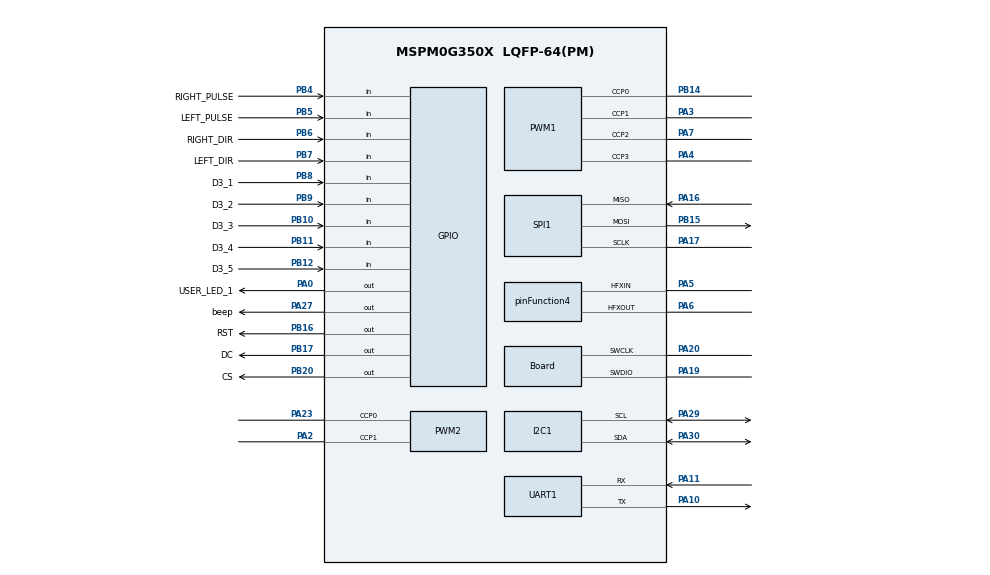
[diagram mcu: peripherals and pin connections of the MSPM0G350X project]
/**
 * @cliArgs --device "MSPM0G350X" --package "LQFP-64(PM)" --part "Default" --product "mspm0_sdk@2.01.00.03"
 * @versions {"tool":"1.20.0+3587"}
 */

/**
 * Import the modules used in this configuration.
 */
const ADC12         = scripting.addModule("/ti/driverlib/ADC12", {}, false);
const ADC121        = ADC12.addInstance();
const Board         = scripting.addModule("/ti/driverlib/Board");
const GPIO          = scripting.addModule("/ti/driverlib/GPIO", {}, false);
const GPIO1         = GPIO.addInstance();
const GPIO2         = GPIO.addInstance();
const GPIO3         = GPIO.addInstance();
const GPIO4         = GPIO.addInstance();
const GPIO5         = GPIO.addInstance();
const GPIO6         = GPIO.addInstance();
const I2C           = scripting.addModule("/ti/driverlib/I2C", {}, false);
const I2C1          = I2C.addInstance();
const PWM           = scripting.addModule("/ti/driverlib/PWM", {}, false);
const PWM1          = PWM.addInstance();
const PWM2          = PWM.addInstance();
const SPI           = scripting.addModule("/ti/driverlib/SPI", {}, false);
const SPI1          = SPI.addInstance();
const SYSCTL        = scripting.addModule("/ti/driverlib/SYSCTL");
const TIMER         = scripting.addModule("/ti/driverlib/TIMER", {}, false);
const TIMER1        = TIMER.addInstance();
const UART          = scripting.addModule("/ti/driverlib/UART", {}, false);
const UART1         = UART.addInstance();
const ProjectConfig = scripting.addModule("/ti/project_config/ProjectConfig");

/**
 * Write custom configuration values to the imported modules.
 */
const divider2       = system.clockTree["HFCLK4MFPCLKDIV"];
divider2.divideValue = 10;

const divider6       = system.clockTree["PLL_CLK2X_DIV"];
divider6.divideValue = 4;

const divider9       = system.clockTree["UDIV"];
divider9.divideValue = 2;

const gate7  = system.clockTree["MFCLKGATE"];
gate7.enable = true;

const gate8  = system.clockTree["MFPCLKGATE"];
gate8.enable = true;

const multiplier2         = system.clockTree["PLL_QDIV"];
multiplier2.multiplyValue = 4;

const mux4       = system.clockTree["EXHFMUX"];
mux4.inputSelect = "EXHFMUX_XTAL";

const mux8       = system.clockTree["HSCLKMUX"];
mux8.inputSelect = "HSCLKMUX_SYSPLL0";

const mux9       = system.clockTree["LFXTMUX"];
mux9.inputSelect = "LFXTMUX_TRUE";

const mux10       = system.clockTree["MFPCLKMUX"];
mux10.inputSelect = "MFPCLKMUX_HFCLK";

const mux12       = system.clockTree["SYSPLLMUX"];
mux12.inputSelect = "zSYSPLLMUX_HFCLK";

const pinFunction4                        = system.clockTree["HFXT"];
pinFunction4.inputFreq                    = 40;
pinFunction4.enable                       = true;
pinFunction4.HFXTStartup                  = 20;
pinFunction4.HFCLKMonitor                 = true;
pinFunction4.peripheral.$assign           = "SYSCTL";
pinFunction4.peripheral.hfxInPin.$assign  = "PA5";
pinFunction4.peripheral.hfxOutPin.$assign = "PA6";

const pinFunction6     = system.clockTree["LFXT"];
pinFunction6.inputFreq = 32.76;

ADC121.$name                      = "ADC12_0";
ADC121.startAdd                   = 1;
ADC121.adcMem1chansel             = "DL_ADC12_INPUT_CHAN_1";
ADC121.enabledInterrupts          = ["DL_ADC12_INTERRUPT_MEM1_RESULT_LOADED"];
ADC121.interruptPriority          = "3";
ADC121.sampleTime0                = "1ms";
ADC121.sampClkSrc                 = "DL_ADC12_CLOCK_ULPCLK";
ADC121.peripheral.$assign         = "ADC0";
ADC121.peripheral.adcPin1.$assign = "PA26";
ADC121.adcPin1Config.$name        = "ti_driverlib_gpio_GPIOPinGeneric3";

Board.peripheral.$assign          = "DEBUGSS";
Board.peripheral.swclkPin.$assign = "PA20";
Board.peripheral.swdioPin.$assign = "PA19";

GPIO1.port                           = "PORTA";
GPIO1.$name                          = "GPIO_LEDS_PORT";
GPIO1.portSegment                    = "Lower";
GPIO1.associatedPins[0].initialValue = "SET";
GPIO1.associatedPins[0].$name        = "USER_LED_1";
GPIO1.associatedPins[0].assignedPin  = "0";
GPIO1.associatedPins[0].pin.$assign  = "PA0";

GPIO2.$name                         = "GPIO_RGB";
GPIO2.port                          = "PORTB";
GPIO2.portSegment                   = "Upper";
GPIO2.associatedPins.create(3);
GPIO2.associatedPins[0].$name       = "RED";
GPIO2.associatedPins[0].assignedPin = "26";
GPIO2.associatedPins[1].$name       = "GREEN";
GPIO2.associatedPins[1].assignedPin = "27";
GPIO2.associatedPins[2].$name       = "BLUE";
GPIO2.associatedPins[2].assignedPin = "22";

GPIO3.$name                              = "GPIO_KEY";
GPIO3.port                               = "PORTB";
GPIO3.associatedPins.create(8);
GPIO3.associatedPins[0].$name            = "KEY_1";
GPIO3.associatedPins[0].direction        = "INPUT";
GPIO3.associatedPins[0].assignedPin      = "21";
GPIO3.associatedPins[0].internalResistor = "PULL_UP";
GPIO3.associatedPins[1].assignedPin      = "23";
GPIO3.associatedPins[1].$name            = "KEY_2";
GPIO3.associatedPins[1].direction        = "INPUT";
GPIO3.associatedPins[1].internalResistor = "PULL_UP";
GPIO3.associatedPins[2].assignedPin      = "24";
GPIO3.associatedPins[2].$name            = "KEY_3";
GPIO3.associatedPins[2].direction        = "INPUT";
GPIO3.associatedPins[2].internalResistor = "PULL_UP";
GPIO3.associatedPins[3].direction        = "INPUT";
GPIO3.associatedPins[3].$name            = "D3_2";
GPIO3.associatedPins[3].internalResistor = "PULL_UP";
GPIO3.associatedPins[3].pin.$assign      = "PB9";
GPIO3.associatedPins[4].$name            = "D3_1";
GPIO3.associatedPins[4].direction        = "INPUT";
GPIO3.associatedPins[4].internalResistor = "PULL_UP";
GPIO3.associatedPins[4].pin.$assign      = "PB8";
GPIO3.associatedPins[5].$name            = "D3_3";
GPIO3.associatedPins[5].direction        = "INPUT";
GPIO3.associatedPins[5].internalResistor = "PULL_UP";
GPIO3.associatedPins[5].pin.$assign      = "PB10";
GPIO3.associatedPins[6].$name            = "D3_4";
GPIO3.associatedPins[6].direction        = "INPUT";
GPIO3.associatedPins[6].internalResistor = "PULL_UP";
GPIO3.associatedPins[6].pin.$assign      = "PB11";
GPIO3.associatedPins[7].$name            = "D3_5";
GPIO3.associatedPins[7].direction        = "INPUT";
GPIO3.associatedPins[7].internalResistor = "PULL_UP";
GPIO3.associatedPins[7].pin.$assign      = "PB12";

GPIO4.$name                         = "GPIO_OLED";
GPIO4.associatedPins.create(3);
GPIO4.associatedPins[0].$name       = "RST";
GPIO4.associatedPins[0].pin.$assign = "PB16";
GPIO4.associatedPins[1].$name       = "DC";
GPIO4.associatedPins[1].pin.$assign = "PB17";
GPIO4.associatedPins[2].$name       = "CS";
GPIO4.associatedPins[2].pin.$assign = "PB20";

GPIO5.$name                               = "GPIO_ENC";
GPIO5.port                                = "PORTB";
GPIO5.associatedPins.create(4);
GPIO5.associatedPins[0].$name             = "RIGHT_DIR";
GPIO5.associatedPins[0].direction         = "INPUT";
GPIO5.associatedPins[0].pin.$assign       = "PB6";
GPIO5.associatedPins[1].direction         = "INPUT";
GPIO5.associatedPins[1].interruptEn       = true;
GPIO5.associatedPins[1].interruptPriority = "1";
GPIO5.associatedPins[1].polarity          = "RISE_FALL";
GPIO5.associatedPins[1].$name             = "RIGHT_PULSE";
GPIO5.associatedPins[1].pin.$assign       = "PB4";
GPIO5.associatedPins[2].$name             = "LEFT_DIR";
GPIO5.associatedPins[2].direction         = "INPUT";
GPIO5.associatedPins[2].pin.$assign       = "PB7";
GPIO5.associatedPins[3].direction         = "INPUT";
GPIO5.associatedPins[3].interruptEn       = true;
GPIO5.associatedPins[3].interruptPriority = "1";
GPIO5.associatedPins[3].polarity          = "RISE_FALL";
GPIO5.associatedPins[3].$name             = "LEFT_PULSE";
GPIO5.associatedPins[3].pin.$assign       = "PB5";

GPIO6.$name                         = "PORTA";
GPIO6.port                          = "PORTA";
GPIO6.associatedPins[0].$name       = "beep";
GPIO6.associatedPins[0].pin.$assign = "PA27";

I2C1.$name                           = "I2C_0";
I2C1.basicEnableController           = true;
I2C1.basicControllerStandardBusSpeed = "FastPlus";
I2C1.peripheral.$assign              = "I2C1";
I2C1.peripheral.sdaPin.$assign       = "PA30";
I2C1.peripheral.sclPin.$assign       = "PA29";
I2C1.sdaPinConfig.$name              = "ti_driverlib_gpio_GPIOPinGeneric10";
I2C1.sclPinConfig.$name              = "ti_driverlib_gpio_GPIOPinGeneric11";

PWM1.$name                              = "PWM_MOTO";
PWM1.pwmMode                            = "EDGE_ALIGN_UP";
PWM1.ccIndex                            = [0,1,2,3];
PWM1.clockPrescale                      = 80;
PWM1.peripheral.$assign                 = "TIMA0";
PWM1.peripheral.ccp0Pin.$assign         = "PB14";
PWM1.peripheral.ccp1Pin.$assign         = "PA3";
PWM1.peripheral.ccp2Pin.$assign         = "PA7";
PWM1.peripheral.ccp3Pin.$assign         = "PA4";
PWM1.PWM_CHANNEL_0.$name                = "ti_driverlib_pwm_PWMTimerCC0";
PWM1.PWM_CHANNEL_1.$name                = "ti_driverlib_pwm_PWMTimerCC1";
PWM1.ccp0PinConfig.direction            = scripting.forceWrite("OUTPUT");
PWM1.ccp0PinConfig.hideOutputInversion  = scripting.forceWrite(false);
PWM1.ccp0PinConfig.onlyInternalResistor = scripting.forceWrite(false);
PWM1.ccp0PinConfig.passedPeripheralType = scripting.forceWrite("Digital");
PWM1.ccp0PinConfig.$name                = "ti_driverlib_gpio_GPIOPinGeneric4";
PWM1.ccp1PinConfig.direction            = scripting.forceWrite("OUTPUT");
PWM1.ccp1PinConfig.hideOutputInversion  = scripting.forceWrite(false);
PWM1.ccp1PinConfig.onlyInternalResistor = scripting.forceWrite(false);
PWM1.ccp1PinConfig.passedPeripheralType = scripting.forceWrite("Digital");
PWM1.ccp1PinConfig.$name                = "ti_driverlib_gpio_GPIOPinGeneric5";
PWM1.PWM_CHANNEL_2.$name                = "ti_driverlib_pwm_PWMTimerCC2";
PWM1.PWM_CHANNEL_2.invert               = true;
PWM1.PWM_CHANNEL_3.$name                = "ti_driverlib_pwm_PWMTimerCC3";
PWM1.PWM_CHANNEL_3.invert               = true;
PWM1.ccp2PinConfig.$name                = "ti_driverlib_gpio_GPIOPinGeneric6";
PWM1.ccp3PinConfig.$name                = "ti_driverlib_gpio_GPIOPinGeneric7";

PWM2.$name                              = "PWM_SERVO";
PWM2.clockDivider                       = 8;
PWM2.pwmMode                            = "EDGE_ALIGN_UP";
PWM2.clockPrescale                      = 100;
PWM2.peripheral.$assign                 = "TIMG7";
PWM2.peripheral.ccp0Pin.$assign         = "PA23";
PWM2.peripheral.ccp1Pin.$assign         = "PA2";
PWM2.PWM_CHANNEL_0.$name                = "ti_driverlib_pwm_PWMTimerCC4";
PWM2.PWM_CHANNEL_1.$name                = "ti_driverlib_pwm_PWMTimerCC5";
PWM2.ccp0PinConfig.direction            = scripting.forceWrite("OUTPUT");
PWM2.ccp0PinConfig.hideOutputInversion  = scripting.forceWrite(false);
PWM2.ccp0PinConfig.onlyInternalResistor = scripting.forceWrite(false);
PWM2.ccp0PinConfig.passedPeripheralType = scripting.forceWrite("Digital");
PWM2.ccp0PinConfig.$name                = "ti_driverlib_gpio_GPIOPinGeneric8";
PWM2.ccp1PinConfig.direction            = scripting.forceWrite("OUTPUT");
PWM2.ccp1PinConfig.hideOutputInversion  = scripting.forceWrite(false);
PWM2.ccp1PinConfig.onlyInternalResistor = scripting.forceWrite(false);
PWM2.ccp1PinConfig.passedPeripheralType = scripting.forceWrite("Digital");
PWM2.ccp1PinConfig.$name                = "ti_driverlib_gpio_GPIOPinGeneric9";

SPI1.$name                      = "SPI_0";
SPI1.targetBitRate              = 1000000;
SPI1.frameFormat                = "MOTO3";
SPI1.polarity                   = "1";
SPI1.phase                      = "1";
SPI1.peripheral.$assign         = "SPI1";
SPI1.peripheral.sclkPin.$assign = "PA17";
SPI1.peripheral.mosiPin.$assign = "PB15";
SPI1.peripheral.misoPin.$assign = "PA16";
SPI1.sclkPinConfig.$name        = "ti_driverlib_gpio_GPIOPinGeneric0";
SPI1.mosiPinConfig.$name        = "ti_driverlib_gpio_GPIOPinGeneric1";
SPI1.misoPinConfig.$name        = "ti_driverlib_gpio_GPIOPinGeneric2";

SYSCTL.clockTreeEn = true;

TIMER1.$name              = "TIMER_0";
TIMER1.interrupts         = ["ZERO"];
TIMER1.timerMode          = "PERIODIC";
TIMER1.timerPeriod        = "1ms";
TIMER1.peripheral.$assign = "TIMG0";

UART1.$name                    = "UART_0";
UART1.calculatedBaudRate       = -2;
UART1.enabledInterrupts        = ["RX"];
UART1.peripheral.$assign       = "UART0";
UART1.peripheral.rxPin.$assign = "PA11";
UART1.peripheral.txPin.$assign = "PA10";
UART1.txPinConfig.$name        = "ti_driverlib_gpio_GPIOPinGeneric12";
UART1.rxPinConfig.$name        = "ti_driverlib_gpio_GPIOPinGeneric13";

ProjectConfig.deviceSpin = "MSPM0G3507";
scripting.suppress("Migrating requires going through the Switch Board or Device menu in the Device View section\\.", ProjectConfig, "deviceSpin");

/**
 * Pinmux solution for unlocked pins/peripherals. This ensures that minor changes to the automatic solver in a future
 * version of the tool will not impact the pinmux you originally saw.  These lines can be completely deleted in order to
 * re-solve from scratch.
 */
GPIO2.associatedPins[0].pin.$suggestSolution = "PB26";
GPIO2.associatedPins[1].pin.$suggestSolution = "PB27";
GPIO2.associatedPins[2].pin.$suggestSolution = "PB22";
GPIO3.associatedPins[0].pin.$suggestSolution = "PB21";
GPIO3.associatedPins[1].pin.$suggestSolution = "PB23";
GPIO3.associatedPins[2].pin.$suggestSolution = "PB24";
